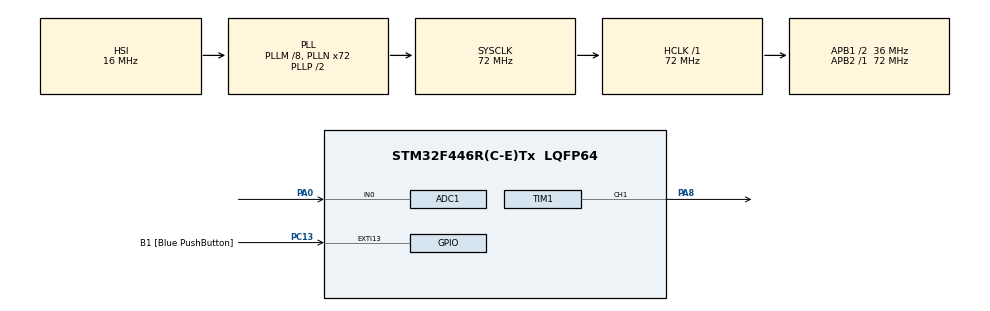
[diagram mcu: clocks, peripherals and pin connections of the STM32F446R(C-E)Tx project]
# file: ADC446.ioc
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ADC1.Channel-0\#ChannelRegularConversion=ADC_CHANNEL_0
ADC1.ContinuousConvMode=ENABLE
ADC1.DMAContinuousRequests=DISABLE
ADC1.NbrOfConversionFlag=1
ADC1.Rank-0\#ChannelRegularConversion=1
ADC1.SamplingTime-0\#ChannelRegularConversion=ADC_SAMPLETIME_112CYCLES
ADC1.master=1
Mcu.Family=STM32F4
Mcu.Name=STM32F446R(C-E)Tx
Mcu.Package=LQFP64
NVIC.PriorityGroup=NVIC_PRIORITYGROUP_0
PA0-WKUP.Signal=ADCx_IN0
PA8.Signal=S_TIM1_CH1
PC13.GPIO_Label=B1 [Blue PushButton]
PC13.GPIO_ModeDefaultEXTI=GPIO_MODE_IT_FALLING
PC13.Signal=GPXTI13
PC14-OSC32_IN.Mode=LSE-External-Oscillator
PC14-OSC32_IN.Signal=RCC_OSC32_IN
PC15-OSC32_OUT.Mode=LSE-External-Oscillator
PC15-OSC32_OUT.Signal=RCC_OSC32_OUT
PH0-OSC_IN.Mode=HSE-External-Oscillator
PH0-OSC_IN.Signal=RCC_OSC_IN
PH1-OSC_OUT.Mode=HSE-External-Oscillator
PH1-OSC_OUT.Signal=RCC_OSC_OUT
ProjectManager.HeapSize=0x200
ProjectManager.StackSize=0x400
ProjectManager.TargetToolchain=STM32CubeIDE
RCC.48MHZClocksFreq_Value=84000000
RCC.AHBFreq_Value=72000000
RCC.APB1CLKDivider=RCC_HCLK_DIV2
RCC.APB1Freq_Value=36000000
RCC.APB1TimFreq_Value=72000000
RCC.APB2Freq_Value=72000000
RCC.APB2TimFreq_Value=72000000
RCC.CortexFreq_Value=72000000
RCC.FLatency-AdvancedSettings=FLASH_LATENCY_2
RCC.HCLKFreq_Value=72000000
RCC.HSE_VALUE=8000000
RCC.HSI_VALUE=16000000
RCC.PLLM=8
RCC.PLLN=72
RCC.SYSCLKFreq_VALUE=72000000
RCC.SYSCLKSource=RCC_SYSCLKSOURCE_PLLCLK
RCC.USBFreq_Value=72000000
RCC.VCOOutputFreq_Value=144000000
SH.ADCx_IN0.0=ADC1_IN0,IN0
SH.S_TIM1_CH1.0=TIM1_CH1,PWM Generation1 CH1
TIM1.Channel-PWM\ Generation1\ CH1=TIM_CHANNEL_1
TIM1.Period=100
TIM1.Prescaler=71
VP_TIM1_VS_ClockSourceINT.Mode=Internal
board=NUCLEO-F446RE

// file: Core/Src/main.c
/* USER CODE BEGIN Header */
/**
  ******************************************************************************
  * @file           : main.c
  * @brief          : Main program body
  ******************************************************************************
  * @attention
  *
  * Copyright (c) 2024 STMicroelectronics.
  * All rights reserved.
  *
  * This software is licensed under terms that can be found in the LICENSE file
  * in the root directory of this software component.
  * If no LICENSE file comes with this software, it is provided AS-IS.
  *
  ******************************************************************************
  */
/* USER CODE END Header */
#include "main.h"

ADC_HandleTypeDef hadc1;

TIM_HandleTypeDef htim1;

/* USER CODE BEGIN PV */
int OffsetB;
float VoltageB;
float AmpCurrentB = 0;
uint16_t adc_samples[10];
float current;
float adc_average=0;
uint16_t readValue;
float sensitivity = 0.1; // 0.1 for 20A Model
float rawVoltage;
float current;
uint16_t adc_samples[10];
uint32_t adc_sum = 0;
uint32_t temp=0;

/* USER CODE END PV */

void SystemClock_Config(void);
static void MX_GPIO_Init(void);
static void MX_ADC1_Init(void);
static void MX_TIM1_Init(void);

int main(void)
{

  /* MCU Configuration--------------------------------------------------------*/

  /* Reset of all peripherals, Initializes the Flash interface and the Systick. */
  HAL_Init();

  /* Configure the system clock */
  SystemClock_Config();

  /* Initialize all configured peripherals */
  MX_GPIO_Init();
  MX_ADC1_Init();
  MX_TIM1_Init();
  /* USER CODE BEGIN 2 */
HAL_TIM_PWM_Start(&htim1, TIM_CHANNEL_1);

  /* USER CODE END 2 */

  /* Infinite loop */
  while (1)
  {

    /* USER CODE BEGIN 3 */

temp=HAL_GetTick();

	 /*  HAL_ADC_Start(&hadc1);
	   HAL_ADC_PollForConversion(&hadc1, 1);
	   readValue = HAL_ADC_GetValue (&hadc1);
	   VoltageB = (float) (readValue*3.3)/4095.0f;
	   current = (VoltageB - 2.513)/0.066f;
	   HAL_Delay(10);*/
for(int i=0;i<2;i++){
	   	           HAL_ADC_Start(&hadc1);
	   	 		   HAL_ADC_PollForConversion(&hadc1, 2);
	   	 		 adc_samples[i] =HAL_ADC_GetValue (&hadc1);
	   	 		  adc_sum+= adc_samples[i] ;
	                     }
	                adc_average=adc_sum/2.0f;
	                VoltageB =( adc_average*3.3)/4095.0f;
	                current = (VoltageB - 2.51 )/0.066f;
	                HAL_Delay(10);
	   	 		     adc_sum=0;

  }
  /* USER CODE END 3 */
}

void SystemClock_Config(void)
{
  RCC_OscInitTypeDef RCC_OscInitStruct = {0};
  RCC_ClkInitTypeDef RCC_ClkInitStruct = {0};

  /** Configure the main internal regulator output voltage
  */
  __HAL_RCC_PWR_CLK_ENABLE();
  __HAL_PWR_VOLTAGESCALING_CONFIG(PWR_REGULATOR_VOLTAGE_SCALE3);

  /** Initializes the RCC Oscillators according to the specified parameters
  * in the RCC_OscInitTypeDef structure.
  */
  RCC_OscInitStruct.OscillatorType = RCC_OSCILLATORTYPE_HSI;
  RCC_OscInitStruct.HSIState = RCC_HSI_ON;
  RCC_OscInitStruct.HSICalibrationValue = RCC_HSICALIBRATION_DEFAULT;
  RCC_OscInitStruct.PLL.PLLState = RCC_PLL_ON;
  RCC_OscInitStruct.PLL.PLLSource = RCC_PLLSOURCE_HSI;
  RCC_OscInitStruct.PLL.PLLM = 8;
  RCC_OscInitStruct.PLL.PLLN = 72;
  RCC_OscInitStruct.PLL.PLLP = RCC_PLLP_DIV2;
  RCC_OscInitStruct.PLL.PLLQ = 2;
  RCC_OscInitStruct.PLL.PLLR = 2;
  if (HAL_RCC_OscConfig(&RCC_OscInitStruct) != HAL_OK)
  {
    Error_Handler();
  }

  /** Initializes the CPU, AHB and APB buses clocks
  */
  RCC_ClkInitStruct.ClockType = RCC_CLOCKTYPE_HCLK|RCC_CLOCKTYPE_SYSCLK
                              |RCC_CLOCKTYPE_PCLK1|RCC_CLOCKTYPE_PCLK2;
  RCC_ClkInitStruct.SYSCLKSource = RCC_SYSCLKSOURCE_PLLCLK;
  RCC_ClkInitStruct.AHBCLKDivider = RCC_SYSCLK_DIV1;
  RCC_ClkInitStruct.APB1CLKDivider = RCC_HCLK_DIV2;
  RCC_ClkInitStruct.APB2CLKDivider = RCC_HCLK_DIV1;

  if (HAL_RCC_ClockConfig(&RCC_ClkInitStruct, FLASH_LATENCY_2) != HAL_OK)
  {
    Error_Handler();
  }
}

static void MX_ADC1_Init(void)
{

  ADC_ChannelConfTypeDef sConfig = {0};

  /** Configure the global features of the ADC (Clock, Resolution, Data Alignment and number of conversion)
  */
  hadc1.Instance = ADC1;
  hadc1.Init.ClockPrescaler = ADC_CLOCK_SYNC_PCLK_DIV2;
  hadc1.Init.Resolution = ADC_RESOLUTION_12B;
  hadc1.Init.ScanConvMode = DISABLE;
  hadc1.Init.ContinuousConvMode = ENABLE;
  hadc1.Init.DiscontinuousConvMode = DISABLE;
  hadc1.Init.ExternalTrigConvEdge = ADC_EXTERNALTRIGCONVEDGE_NONE;
  hadc1.Init.ExternalTrigConv = ADC_SOFTWARE_START;
  hadc1.Init.DataAlign = ADC_DATAALIGN_RIGHT;
  hadc1.Init.NbrOfConversion = 1;
  hadc1.Init.DMAContinuousRequests = DISABLE;
  hadc1.Init.EOCSelection = ADC_EOC_SINGLE_CONV;
  if (HAL_ADC_Init(&hadc1) != HAL_OK)
  {
    Error_Handler();
  }

  /** Configure for the selected ADC regular channel its corresponding rank in the sequencer and its sample time.
  */
  sConfig.Channel = ADC_CHANNEL_0;
  sConfig.Rank = 1;
  sConfig.SamplingTime = ADC_SAMPLETIME_112CYCLES;
  if (HAL_ADC_ConfigChannel(&hadc1, &sConfig) != HAL_OK)
  {
    Error_Handler();
  }

}

static void MX_TIM1_Init(void)
{

  TIM_ClockConfigTypeDef sClockSourceConfig = {0};
  TIM_MasterConfigTypeDef sMasterConfig = {0};
  TIM_OC_InitTypeDef sConfigOC = {0};
  TIM_BreakDeadTimeConfigTypeDef sBreakDeadTimeConfig = {0};

  htim1.Instance = TIM1;
  htim1.Init.Prescaler = 71;
  htim1.Init.CounterMode = TIM_COUNTERMODE_UP;
  htim1.Init.Period = 100;
  htim1.Init.ClockDivision = TIM_CLOCKDIVISION_DIV1;
  htim1.Init.RepetitionCounter = 0;
  htim1.Init.AutoReloadPreload = TIM_AUTORELOAD_PRELOAD_DISABLE;
  if (HAL_TIM_Base_Init(&htim1) != HAL_OK)
  {
    Error_Handler();
  }
  sClockSourceConfig.ClockSource = TIM_CLOCKSOURCE_INTERNAL;
  if (HAL_TIM_ConfigClockSource(&htim1, &sClockSourceConfig) != HAL_OK)
  {
    Error_Handler();
  }
  if (HAL_TIM_PWM_Init(&htim1) != HAL_OK)
  {
    Error_Handler();
  }
  sMasterConfig.MasterOutputTrigger = TIM_TRGO_RESET;
  sMasterConfig.MasterSlaveMode = TIM_MASTERSLAVEMODE_DISABLE;
  if (HAL_TIMEx_MasterConfigSynchronization(&htim1, &sMasterConfig) != HAL_OK)
  {
    Error_Handler();
  }
  sConfigOC.OCMode = TIM_OCMODE_PWM1;
  sConfigOC.Pulse = 0;
  sConfigOC.OCPolarity = TIM_OCPOLARITY_HIGH;
  sConfigOC.OCNPolarity = TIM_OCNPOLARITY_HIGH;
  sConfigOC.OCFastMode = TIM_OCFAST_DISABLE;
  sConfigOC.OCIdleState = TIM_OCIDLESTATE_RESET;
  sConfigOC.OCNIdleState = TIM_OCNIDLESTATE_RESET;
  if (HAL_TIM_PWM_ConfigChannel(&htim1, &sConfigOC, TIM_CHANNEL_1) != HAL_OK)
  {
    Error_Handler();
  }
  sBreakDeadTimeConfig.OffStateRunMode = TIM_OSSR_DISABLE;
  sBreakDeadTimeConfig.OffStateIDLEMode = TIM_OSSI_DISABLE;
  sBreakDeadTimeConfig.LockLevel = TIM_LOCKLEVEL_OFF;
  sBreakDeadTimeConfig.DeadTime = 0;
  sBreakDeadTimeConfig.BreakState = TIM_BREAK_DISABLE;
  sBreakDeadTimeConfig.BreakPolarity = TIM_BREAKPOLARITY_HIGH;
  sBreakDeadTimeConfig.AutomaticOutput = TIM_AUTOMATICOUTPUT_DISABLE;
  if (HAL_TIMEx_ConfigBreakDeadTime(&htim1, &sBreakDeadTimeConfig) != HAL_OK)
  {
    Error_Handler();
  }
  HAL_TIM_MspPostInit(&htim1);

}

static void MX_GPIO_Init(void)
{
  GPIO_InitTypeDef GPIO_InitStruct = {0};

  /* GPIO Ports Clock Enable */
  __HAL_RCC_GPIOC_CLK_ENABLE();
  __HAL_RCC_GPIOH_CLK_ENABLE();
  __HAL_RCC_GPIOA_CLK_ENABLE();

  /*Configure GPIO pin : B1_Pin */
  GPIO_InitStruct.Pin = B1_Pin;
  GPIO_InitStruct.Mode = GPIO_MODE_IT_FALLING;
  GPIO_InitStruct.Pull = GPIO_NOPULL;
  HAL_GPIO_Init(B1_GPIO_Port, &GPIO_InitStruct);

}

void Error_Handler(void)
{
  __disable_irq();
  while (1)
  {
  }
}
